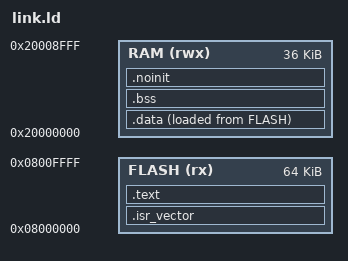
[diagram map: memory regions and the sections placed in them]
ENTRY(Reset_Handler)

MEMORY
{
  FLASH (rx)  : ORIGIN = 0x08000000, LENGTH = 64K
  RAM   (rwx) : ORIGIN = 0x20000000, LENGTH = 36K
}

_estack = ORIGIN(RAM) + LENGTH(RAM);

SECTIONS
{
  .isr_vector :
  {
    KEEP(*(.isr_vector))
  } > FLASH

  .text :
  {
    *(.text*)
    *(.rodata*)
    KEEP(*(.init))
    KEEP(*(.fini))
  } > FLASH

  /* Discard C++ exception unwind tables (not needed on Cortex-M0+) */
  /DISCARD/ :
  {
    *(.ARM.exidx*)
    *(.ARM.extab*)
  }

  _sidata = LOADADDR(.data);

  .data :
  {
    _sdata = .;
    *(.data*)
    _edata = .;
  } > RAM AT> FLASH

  .bss :
  {
    _sbss = .;
    *(.bss*)
    *(COMMON)
    _ebss = .;
  } > RAM

  .noinit (NOLOAD) :
  {
    _snoinit = .;
    *(.noinit*)
    _enoinit = .;
  } > RAM

  /* Heap start symbol required by _sbrk (libnosys) */
  end = _ebss;
}
